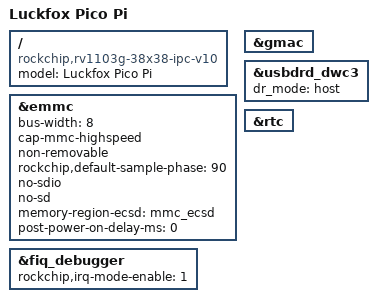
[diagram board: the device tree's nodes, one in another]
// SPDX-License-Identifier: (GPL-2.0+ OR MIT)
/*
 * Copyright (c) 2022 Rockchip Electronics Co., Ltd.
 */

/dts-v1/;
#include "rv1106.dtsi"
#include "rv1106-luckfox-pico-ultra-ipc.dtsi"
#include <dt-bindings/input/input.h>
#include <dt-bindings/display/media-bus-format.h>

/ {
	model = "Luckfox Pico Pi";
	compatible = "rockchip,rv1103g-38x38-ipc-v10", "rockchip,rv1106";
};


/**********EMMC**********/
&emmc {
	bus-width = <8>;
	cap-mmc-highspeed;
	non-removable;
	// mmc-hs200-1_8v;
	rockchip,default-sample-phase = <90>;
	no-sdio;
	no-sd;
	memory-region-ecsd = <&mmc_ecsd>;
	post-power-on-delay-ms = <0>;
	status = "okay";
};

&fiq_debugger {
	rockchip,irq-mode-enable = <1>;
	status = "okay";
};

/**********ETH**********/
&gmac {
	status = "okay";
};

/**********USB**********/
&usbdrd_dwc3 {
	status = "okay";
	dr_mode = "host";
};

/**********RTC**********/
&rtc {
	status = "okay";
};

